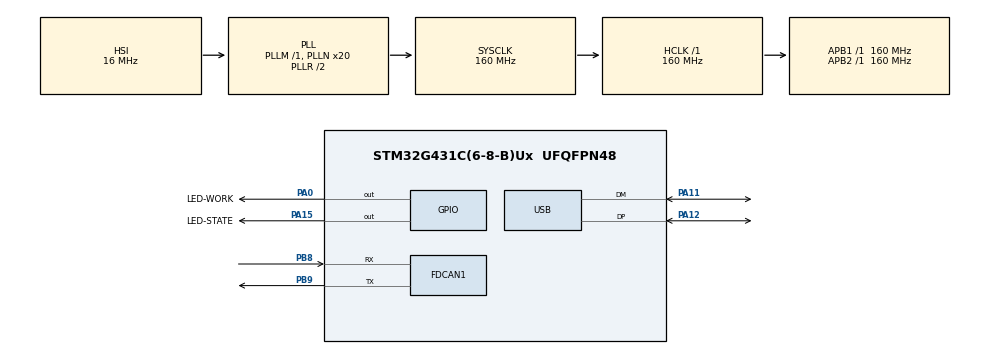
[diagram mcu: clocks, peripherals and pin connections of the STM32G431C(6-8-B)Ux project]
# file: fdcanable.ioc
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FDCAN1.CalculateBaudRateNominal=3333333
FDCAN1.CalculateTimeBitNominal=300
FDCAN1.CalculateTimeQuantumNominal=100.0
FDCAN1.StdFiltersNbr=3
Mcu.Family=STM32G4
Mcu.Name=STM32G431C(6-8-B)Ux
Mcu.Package=UFQFPN48
NVIC.FDCAN1_IT0_IRQn=true\:0\:0\:false\:false\:true\:true\:true\:true
NVIC.FDCAN1_IT1_IRQn=true\:0\:0\:false\:false\:true\:true\:true\:true
NVIC.PriorityGroup=NVIC_PRIORITYGROUP_4
NVIC.TIM3_IRQn=true\:0\:0\:false\:false\:true\:true\:true\:true
NVIC.USB_LP_IRQn=true\:0\:0\:false\:false\:true\:false\:true\:true
PA0.GPIO_Label=LED-WORK
PA0.Signal=GPIO_Output
PA11.Mode=Device
PA11.Signal=USB_DM
PA12.Mode=Device
PA12.Signal=USB_DP
PA13.Mode=Serial_Wire
PA13.Signal=SYS_JTMS-SWDIO
PA14.Mode=Serial_Wire
PA14.Signal=SYS_JTCK-SWCLK
PA15.GPIO_Label=LED-STATE
PA15.Signal=GPIO_Output
PB8-BOOT0.Mode=FDCAN_Activate
PB8-BOOT0.Signal=FDCAN1_RX
PB9.Mode=FDCAN_Activate
PB9.Signal=FDCAN1_TX
ProjectManager.HeapSize=0x1000
ProjectManager.StackSize=0x1000
ProjectManager.TargetToolchain=CMake
RCC.ADC12Freq_Value=160000000
RCC.AHBFreq_Value=160000000
RCC.APB1Freq_Value=160000000
RCC.APB1TimFreq_Value=160000000
RCC.APB2Freq_Value=160000000
RCC.APB2TimFreq_Value=160000000
RCC.CK48CLockSelection=RCC_USBCLKSOURCE_HSI48
RCC.CortexFreq_Value=160000000
RCC.EXTERNAL_CLOCK_VALUE=12288000
RCC.HCLKFreq_Value=160000000
RCC.HSE_VALUE=8000000
RCC.HSI48_VALUE=48000000
RCC.HSI_VALUE=16000000
RCC.LSE_VALUE=32768
RCC.PLLN=20
RCC.PLLQ=RCC_PLLQ_DIV4
RCC.SYSCLKFreq_VALUE=160000000
RCC.SYSCLKSource=RCC_SYSCLKSOURCE_PLLCLK
RCC.USBFreq_Value=48000000
RCC.VCOOutputFreq_Value=320000000
TIM3.AutoReloadPreload=TIM_AUTORELOAD_PRELOAD_ENABLE
TIM3.PeriodNoDither=10000-1
TIM3.Prescaler=16000-1
USB.Sof_enable=DISABLE
USB_DEVICE.CLASS_NAME_FS=CDC
USB_DEVICE.MANUFACTURER_STRING=TONWOO
USB_DEVICE.PID_CDC_FS=0x117e
USB_DEVICE.PRODUCT_STRING_CDC_FS=FDCANABLE
USB_DEVICE.VID=0x16d0
USB_DEVICE.VirtualMode=Cdc
USB_DEVICE.VirtualModeFS=Cdc_FS
VP_SYS_VS_DBSignals.Mode=DisableDeadBatterySignals
VP_TIM3_VS_ClockSourceINT.Mode=Internal
VP_USB_DEVICE_VS_USB_DEVICE_CDC_FS.Mode=CDC_FS
board=custom

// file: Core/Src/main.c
/* USER CODE BEGIN Header */
/**
 ******************************************************************************
 * @file           : main.c
 * @brief          : Main program body
 ******************************************************************************
 * @attention
 *
 * Copyright (c) 2026 STMicroelectronics.
 * All rights reserved.
 *
 * This software is licensed under terms that can be found in the LICENSE file
 * in the root directory of this software component.
 * If no LICENSE file comes with this software, it is provided AS-IS.
 *
 ******************************************************************************
 */
/* USER CODE END Header */
#include "main.h"
#include "fdcan.h"
#include "tim.h"
#include "usb_device.h"
#include "gpio.h"

void SystemClock_Config(void);

int main(void)
{

  /* MCU Configuration--------------------------------------------------------*/

  /* Reset of all peripherals, Initializes the Flash interface and the Systick. */
  HAL_Init();

  /* Configure the system clock */
  SystemClock_Config();

  /* Initialize all configured peripherals */
  MX_GPIO_Init();
  MX_FDCAN1_Init();
  MX_USB_Device_Init();
  MX_TIM3_Init();
  /* USER CODE BEGIN 2 */

  HAL_TIM_Base_Start_IT(&htim3);

  void AppRun();
  AppRun();
  /* USER CODE END 2 */

  /* Infinite loop */
  while (1) {

  }
}

void SystemClock_Config(void)
{
  RCC_OscInitTypeDef RCC_OscInitStruct = {0};
  RCC_ClkInitTypeDef RCC_ClkInitStruct = {0};

  /** Configure the main internal regulator output voltage
  */
  HAL_PWREx_ControlVoltageScaling(PWR_REGULATOR_VOLTAGE_SCALE1_BOOST);

  /** Initializes the RCC Oscillators according to the specified parameters
  * in the RCC_OscInitTypeDef structure.
  */
  RCC_OscInitStruct.OscillatorType = RCC_OSCILLATORTYPE_HSI|RCC_OSCILLATORTYPE_HSI48;
  RCC_OscInitStruct.HSIState = RCC_HSI_ON;
  RCC_OscInitStruct.HSICalibrationValue = RCC_HSICALIBRATION_DEFAULT;
  RCC_OscInitStruct.HSI48State = RCC_HSI48_ON;
  RCC_OscInitStruct.PLL.PLLState = RCC_PLL_ON;
  RCC_OscInitStruct.PLL.PLLSource = RCC_PLLSOURCE_HSI;
  RCC_OscInitStruct.PLL.PLLM = RCC_PLLM_DIV1;
  RCC_OscInitStruct.PLL.PLLN = 20;
  RCC_OscInitStruct.PLL.PLLP = RCC_PLLP_DIV2;
  RCC_OscInitStruct.PLL.PLLQ = RCC_PLLQ_DIV4;
  RCC_OscInitStruct.PLL.PLLR = RCC_PLLR_DIV2;
  if (HAL_RCC_OscConfig(&RCC_OscInitStruct) != HAL_OK)
  {
    Error_Handler();
  }

  /** Initializes the CPU, AHB and APB buses clocks
  */
  RCC_ClkInitStruct.ClockType = RCC_CLOCKTYPE_HCLK|RCC_CLOCKTYPE_SYSCLK
                              |RCC_CLOCKTYPE_PCLK1|RCC_CLOCKTYPE_PCLK2;
  RCC_ClkInitStruct.SYSCLKSource = RCC_SYSCLKSOURCE_PLLCLK;
  RCC_ClkInitStruct.AHBCLKDivider = RCC_SYSCLK_DIV1;
  RCC_ClkInitStruct.APB1CLKDivider = RCC_HCLK_DIV1;
  RCC_ClkInitStruct.APB2CLKDivider = RCC_HCLK_DIV1;

  if (HAL_RCC_ClockConfig(&RCC_ClkInitStruct, FLASH_LATENCY_4) != HAL_OK)
  {
    Error_Handler();
  }
}

void Error_Handler(void)
{
  __disable_irq();
  while (1) {
  }
}
#ifdef USE_FULL_ASSERT
/**
  * @brief  Reports the name of the source file and the source line number
  *         where the assert_param error has occurred.
  * @param  file: pointer to the source file name
  * @param  line: assert_param error line source number
  * @retval None
  */
void assert_failed(uint8_t *file, uint32_t line)
{
  /* USER CODE BEGIN 6 */
  /* User can add his own implementation to report the file name and line
     number, ex: printf("Wrong parameters value: file %s on line %d\r\n", file,
     line) */
  /* USER CODE END 6 */
}
#endif /* USE_FULL_ASSERT */
